# STM32F413 register map
File version: 1.5
CPU: CM4 r0p1, little endian, MPU, FPU, 4 interrupt priority bits
Registers are 32-bit, read-write, reset 0x0 unless marked. A register's access mark holds for its fields unless they carry their own. Offsets are from the block's base; [hi:lo] are bit positions; {n}, {i} and the like mark numbered series.

## LPTIM — Low power timer
Base 0x40002400
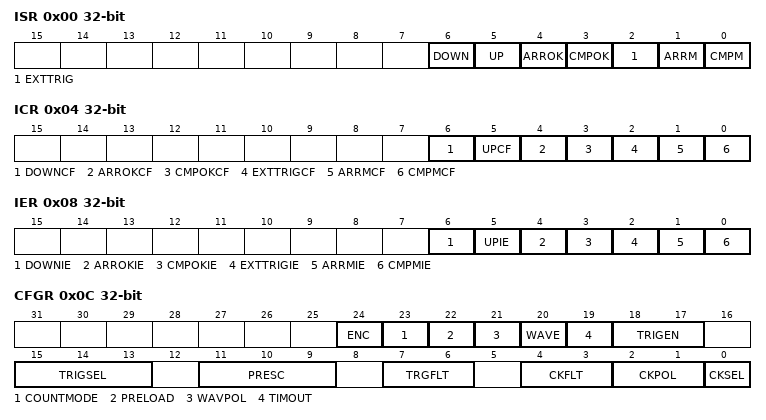
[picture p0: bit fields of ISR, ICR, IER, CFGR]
0x00 ISR ro — Interrupt and Status Register
  [6] DOWN — Counter direction change up to down
  [5] UP — Counter direction change down to up
  [4] ARROK — Autoreload register update OK
  [3] CMPOK — Compare register update OK
  [2] EXTTRIG — External trigger edge event
  [1] ARRM — Autoreload match
  [0] CMPM — Compare match
0x04 ICR wo — Interrupt Clear Register
  [6] DOWNCF — Direction change to down Clear Flag
  [5] UPCF — Direction change to UP Clear Flag
  [4] ARROKCF — Autoreload register update OK Clear Flag
  [3] CMPOKCF — Compare register update OK Clear Flag
  [2] EXTTRIGCF — External trigger valid edge Clear Flag
  [1] ARRMCF — Autoreload match Clear Flag
  [0] CMPMCF — compare match Clear Flag
0x08 IER — Interrupt Enable Register
  [6] DOWNIE — Direction change to down Interrupt Enable
  [5] UPIE — Direction change to UP Interrupt Enable
  [4] ARROKIE — Autoreload register update OK Interrupt Enable
  [3] CMPOKIE — Compare register update OK Interrupt Enable
  [2] EXTTRIGIE — External trigger valid edge Interrupt Enable
  [1] ARRMIE — Autoreload match Interrupt Enable
  [0] CMPMIE — Compare match Interrupt Enable
0x0C CFGR — Configuration Register
  [24] ENC — Encoder mode enable
  [23] COUNTMODE — counter mode enabled
  [22] PRELOAD — Registers update mode
  [21] WAVPOL — Waveform shape polarity
  [20] WAVE — Waveform shape
  [19] TIMOUT — Timeout enable
  [18:17] TRIGEN — Trigger enable and polarity
  [15:13] TRIGSEL — Trigger selector
  [11:9] PRESC — Clock prescaler
  [7:6] TRGFLT — Configurable digital filter for trigger
  [4:3] CKFLT — Configurable digital filter for external clock
  [2:1] CKPOL — Clock Polarity
  [0] CKSEL — Clock selector
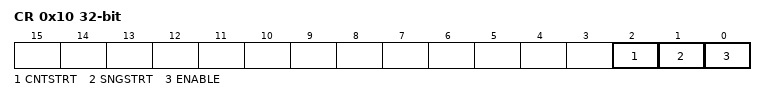
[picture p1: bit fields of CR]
0x10 CR — Control Register
  [2] CNTSTRT — Timer start in continuous mode
  [1] SNGSTRT — LPTIM start in single mode
  [0] ENABLE — LPTIM Enable
0x14 CMP — Compare Register
  [15:0] CMP — Compare value
0x18 ARR reset 0x1 — Autoreload Register
  [15:0] ARR — Auto reload value
0x1C CNT ro — Counter Register
  [15:0] CNT — Counter value

## NVIC — Nested Vectored Interrupt Controller
Base 0xE000E100
{0x0+4i} ISER{i} (i=0..2) — Interrupt Set-Enable Register
  [31:0] SETENA
{0x80+4i} ICER{i} (i=0..2) — Interrupt Clear-Enable Register
  [31:0] CLRENA
{0x100+4i} ISPR{i} (i=0..2) — Interrupt Set-Pending Register
  [31:0] SETPEND
{0x180+4i} ICPR{i} (i=0..2) — Interrupt Clear-Pending Register
  [31:0] CLRPEND
{0x200+4i} IABR{i} ro (i=0..2) — Interrupt Active Bit Register
  [31:0] ACTIVE
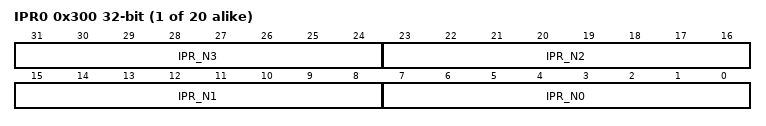
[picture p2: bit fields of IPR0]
{0x300+4i} IPR{i} (i=0..19) — Interrupt Priority Register
  [8n+7:8n] IPR_N{n} (n=0..3)

## PWR — Power control
Base 0x40007000
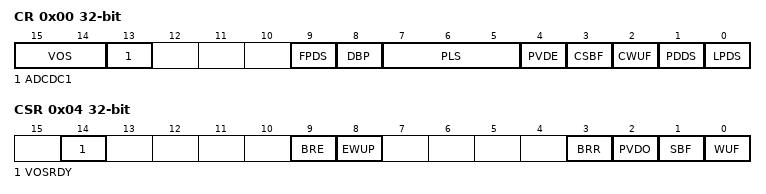
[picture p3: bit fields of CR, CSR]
0x00 CR — power control register
  [15:14] VOS — Regulator voltage scaling output selection
  [13] ADCDC1
  [9] FPDS — Flash power down in Stop mode
  [8] DBP — Disable backup domain write protection
  [7:5] PLS — PVD level selection
  [4] PVDE — Power voltage detector enable
  [3] CSBF — Clear standby flag
  [2] CWUF — Clear wakeup flag
  [1] PDDS — Power down deepsleep
  [0] LPDS — Low-power deep sleep
0x04 CSR access per field — power control/status register
  [14] VOSRDY rw — Regulator voltage scaling output selection ready bit
  [9] BRE rw — Backup regulator enable
  [8] EWUP rw — Enable WKUP pin
  [3] BRR ro — Backup regulator ready
  [2] PVDO ro — PVD output
  [1] SBF ro — Standby flag
  [0] WUF ro — Wakeup flag

## QUADSPI — QuadSPI interface
Base 0xA0001000
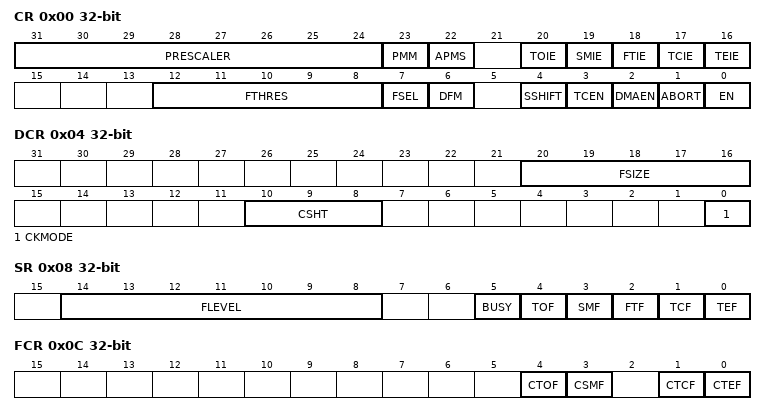
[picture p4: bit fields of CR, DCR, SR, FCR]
0x00 CR — control register
  [31:24] PRESCALER — Clock prescaler
  [23] PMM — Polling match mode
  [22] APMS — Automatic poll mode stop
  [20] TOIE — TimeOut interrupt enable
  [19] SMIE — Status match interrupt enable
  [18] FTIE — FIFO threshold interrupt enable
  [17] TCIE — Transfer complete interrupt enable
  [16] TEIE — Transfer error interrupt enable
  [12:8] FTHRES — IFO threshold level
  [7] FSEL — FLASH memory selection
  [6] DFM — Dual-flash mode
  [4] SSHIFT — Sample shift
  [3] TCEN — Timeout counter enable
  [2] DMAEN — DMA enable
  [1] ABORT — Abort request
  [0] EN — Enable
0x04 DCR — device configuration register
  [20:16] FSIZE — FLASH memory size
  [10:8] CSHT — Chip select high time
  [0] CKMODE — Mode 0 / mode 3
0x08 SR ro — status register
  [14:8] FLEVEL — FIFO level
  [5] BUSY
  [4] TOF — Timeout flag
  [3] SMF — Status match flag
  [2] FTF — FIFO threshold flag
  [1] TCF — Transfer complete flag
  [0] TEF — Transfer error flag
0x0C FCR — flag clear register
  [4] CTOF — Clear timeout flag
  [3] CSMF — Clear status match flag
  [1] CTCF — Clear transfer complete flag
  [0] CTEF — Clear transfer error flag
0x10 DLR — data length register
  [31:0] DL — Data length
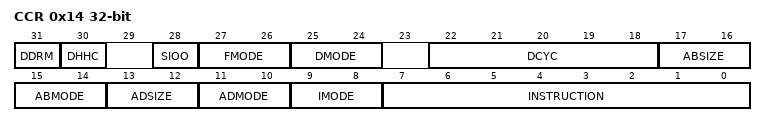
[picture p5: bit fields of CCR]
0x14 CCR — communication configuration register
  [31] DDRM — Double data rate mode
  [30] DHHC — DDR hold half cycle
  [28] SIOO — Send instruction only once mode
  [27:26] FMODE — Functional mode
  [25:24] DMODE — Data mode
  [22:18] DCYC — Number of dummy cycles
  [17:16] ABSIZE — Alternate bytes size
  [15:14] ABMODE — Alternate bytes mode
  [13:12] ADSIZE — Address size
  [11:10] ADMODE — Address mode
  [9:8] IMODE — Instruction mode
  [7:0] INSTRUCTION
0x18 AR — address register
  [31:0] ADDRESS
0x1C ABR
  [31:0] ALTERNATE
0x20 DR — data register
  [31:0] DATA
0x24 PSMKR — polling status mask register
  [31:0] MASK — Status mask
0x28 PSMAR — polling status match register
  [31:0] MATCH — Status match
0x2C PIR — polling interval register
  [15:0] INTERVAL — Polling interval
0x30 LPTR — low-power timeout register
  [15:0] TIMEOUT — Timeout period
